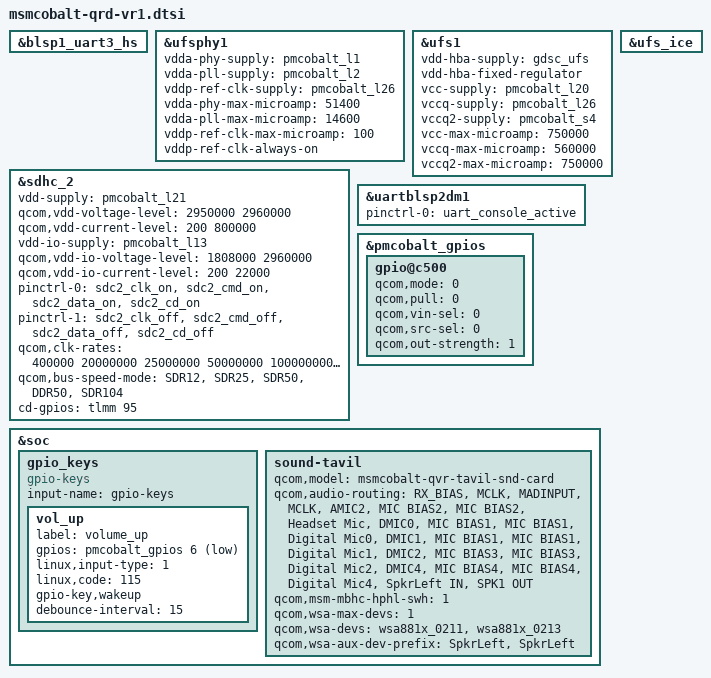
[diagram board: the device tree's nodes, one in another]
/* Copyright (c) 2016, The Linux Foundation. All rights reserved.
 *
 * This program is free software; you can redistribute it and/or modify
 * it under the terms of the GNU General Public License version 2 and
 * only version 2 as published by the Free Software Foundation.
 *
 * This program is distributed in the hope that it will be useful,
 * but WITHOUT ANY WARRANTY; without even the implied warranty of
 * MERCHANTABILITY or FITNESS FOR A PARTICULAR PURPOSE.  See the
 * GNU General Public License for more details.
 */

#include <dt-bindings/interrupt-controller/irq.h>
#include "msmcobalt-pinctrl.dtsi"

&blsp1_uart3_hs {
	status = "ok";
};

&ufsphy1 {
	vdda-phy-supply = <&pmcobalt_l1>;
	vdda-pll-supply = <&pmcobalt_l2>;
	vddp-ref-clk-supply = <&pmcobalt_l26>;
	vdda-phy-max-microamp = <51400>;
	vdda-pll-max-microamp = <14600>;
	vddp-ref-clk-max-microamp = <100>;
	vddp-ref-clk-always-on;
	status = "ok";
};

&ufs1 {
	vdd-hba-supply = <&gdsc_ufs>;
	vdd-hba-fixed-regulator;
	vcc-supply = <&pmcobalt_l20>;
	vccq-supply = <&pmcobalt_l26>;
	vccq2-supply = <&pmcobalt_s4>;
	vcc-max-microamp = <750000>;
	vccq-max-microamp = <560000>;
	vccq2-max-microamp = <750000>;
	status = "ok";
};

&ufs_ice {
	status = "ok";
};

&sdhc_2 {
	vdd-supply = <&pmcobalt_l21>;
	qcom,vdd-voltage-level = <2950000 2960000>;
	qcom,vdd-current-level = <200 800000>;

	vdd-io-supply = <&pmcobalt_l13>;
	qcom,vdd-io-voltage-level = <1808000 2960000>;
	qcom,vdd-io-current-level = <200 22000>;

	pinctrl-names = "active", "sleep";
	pinctrl-0 = <&sdc2_clk_on  &sdc2_cmd_on &sdc2_data_on &sdc2_cd_on>;
	pinctrl-1 = <&sdc2_clk_off &sdc2_cmd_off &sdc2_data_off &sdc2_cd_off>;

	qcom,clk-rates = <400000 20000000 25000000
				50000000 100000000 200000000>;
	qcom,bus-speed-mode = "SDR12", "SDR25", "SDR50", "DDR50", "SDR104";

	cd-gpios = <&tlmm 95 0x0>;

	status = "ok";
};

&uartblsp2dm1 {
	status = "ok";
	pinctrl-names = "default";
	pinctrl-0 = <&uart_console_active>;
};

&pmcobalt_gpios {
	/* GPIO 6 for Vol+ Key */
	gpio@c500 {
		status = "okay";
		qcom,mode = <0>;
		qcom,pull = <0>;
		qcom,vin-sel = <0>;
		qcom,src-sel = <0>;
		qcom,out-strength = <1>;
	};
};

&soc {
	gpio_keys {
		compatible = "gpio-keys";
		input-name = "gpio-keys";
		status = "okay";

		vol_up {
			label = "volume_up";
			gpios = <&pmcobalt_gpios 6 0x1>;
			linux,input-type = <1>;
			linux,code = <115>;
			gpio-key,wakeup;
			debounce-interval = <15>;
		};
	};

	sound-tavil {
		qcom,model = "msmcobalt-qvr-tavil-snd-card";
		qcom,audio-routing =
			"RX_BIAS", "MCLK",
			"MADINPUT", "MCLK",
			"AMIC2", "MIC BIAS2",
			"MIC BIAS2", "Headset Mic",
			"DMIC0", "MIC BIAS1",
			"MIC BIAS1", "Digital Mic0",
			"DMIC1", "MIC BIAS1",
			"MIC BIAS1", "Digital Mic1",
			"DMIC2", "MIC BIAS3",
			"MIC BIAS3", "Digital Mic2",
			"DMIC4", "MIC BIAS4",
			"MIC BIAS4", "Digital Mic4",
			"SpkrLeft IN", "SPK1 OUT";

		qcom,msm-mbhc-hphl-swh = <1>;
		/delete-property/ qcom,us-euro-gpios;
		/delete-property/ qcom,hph-en0-gpio;
		/delete-property/ qcom,hph-en0-gpio;

		qcom,wsa-max-devs = <1>;
		qcom,wsa-devs = <&wsa881x_0211>, <&wsa881x_0213>;
		qcom,wsa-aux-dev-prefix = "SpkrLeft", "SpkrLeft";
	};
};
